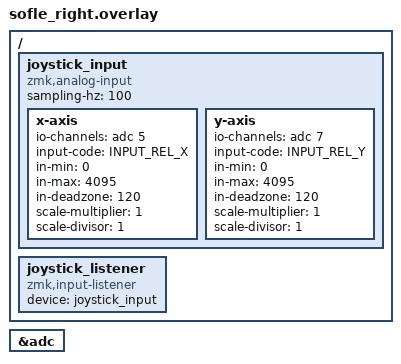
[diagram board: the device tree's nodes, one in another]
/* sofle_right.overlay */
#include <dt-bindings/zmk/input_transform.h>
#include <dt-bindings/zmk/mouse.h>
#include <zephyr/dt-bindings/input/input-event-codes.h>

/* 1. Enable the ADC (Analog Digital Converter) */
&adc {
    status = "okay";
};

/ {
    /* 2. Define the Joystick Input */
    joystick_input: joystick_input {
        compatible = "zmk,analog-input";
        /* Use the ADC driver */
        sampling-hz = <100>; /* Poll 100 times a second */

        /* Define X Axis (Horizontal) on Pin P0.29 (A5 / AIN5) */
        x-axis {
            io-channels = <&adc 5>;
            input-code = <INPUT_REL_X>; /* Report as Mouse X */
            /* Calibrate: min, center, max, deadzone */
            /* You may need to tweak these numbers for your specific stick! */
            /* If Left goes Right, swap these two numbers (4095 and 0) */
            in-min = <0>;
            in-max = <4095>;
            in-deadzone = <120>;
            /* Smoothing: Flips the direction if needed */
            scale-multiplier = <1>;
            scale-divisor = <1>;
        };

        /* Define Y Axis (Vertical) on Pin P0.31 (A7 / AIN7) */
        y-axis {
            /* If Up/Down is swapped with Left/Right, change this to <&adc 5> */
            io-channels = <&adc 7>;
            input-code = <INPUT_REL_Y>;

            /* If Up goes Down, swap these two numbers (4095 and 0) */
            in-min = <0>;
            in-max = <4095>;

            in-deadzone = <120>;
            scale-multiplier = <1>;
            scale-divisor = <1>;
        };
    };

    /* 3. Link the Joystick to the Mouse Behavior */
    /* This listens to the joystick and sends mouse commands */
    joystick_listener {
        compatible = "zmk,input-listener";
        device = <&joystick_input>;

        // /* When X axis moves, call Mouse Move X */
        // bindings = <&ib_input_transform INPUT_REL_X &mmv MOVE_X>,
        //            <&ib_input_transform INPUT_REL_Y &mmv MOVE_Y>;

        /* Speed Scaling (Global) */
        /* To make it faster, increase the multiplier in the behavior config below */
    };
};
